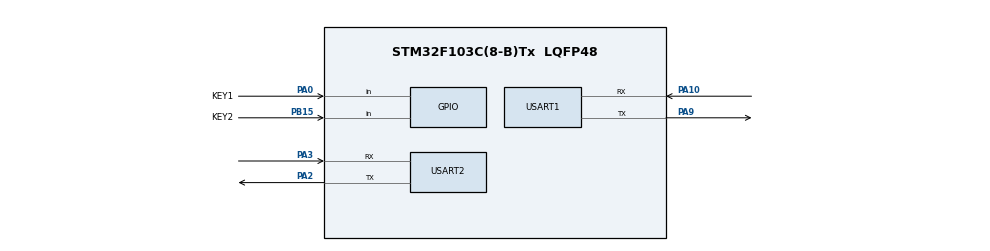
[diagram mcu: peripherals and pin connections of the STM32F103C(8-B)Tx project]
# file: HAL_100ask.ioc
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Mcu.Family=STM32F1
Mcu.Name=STM32F103C(8-B)Tx
Mcu.Package=LQFP48
NVIC.PriorityGroup=NVIC_PRIORITYGROUP_4
NVIC.USART2_IRQn=true\:0\:0\:false\:false\:true\:true\:true\:true
PA0-WKUP.GPIO_Label=KEY1
PA0-WKUP.GPIO_PuPd=GPIO_PULLDOWN
PA0-WKUP.Signal=GPIO_Input
PA10.Mode=Asynchronous
PA10.Signal=USART1_RX
PA13.Mode=Serial_Wire
PA13.Signal=SYS_JTMS-SWDIO
PA14.Mode=Serial_Wire
PA14.Signal=SYS_JTCK-SWCLK
PA2.Mode=Asynchronous
PA2.Signal=USART2_TX
PA3.Mode=Asynchronous
PA3.Signal=USART2_RX
PA9.Mode=Asynchronous
PA9.Signal=USART1_TX
PB15.GPIO_Label=KEY2
PB15.GPIO_PuPd=GPIO_PULLUP
PB15.Signal=GPIO_Input
PC14-OSC32_IN.Mode=LSE-External-Oscillator
PC14-OSC32_IN.Signal=RCC_OSC32_IN
PC15-OSC32_OUT.Mode=LSE-External-Oscillator
PC15-OSC32_OUT.Signal=RCC_OSC32_OUT
PD0-OSC_IN.Mode=HSE-External-Oscillator
PD0-OSC_IN.Signal=RCC_OSC_IN
PD1-OSC_OUT.Mode=HSE-External-Oscillator
PD1-OSC_OUT.Signal=RCC_OSC_OUT
ProjectManager.HeapSize=0x200
ProjectManager.StackSize=0x400
ProjectManager.TargetToolchain=MDK-ARM V5.32
RCC.AHBFreq_Value=72000000
RCC.APB1CLKDivider=RCC_HCLK_DIV2
RCC.APB1Freq_Value=36000000
RCC.APB1TimFreq_Value=72000000
RCC.APB2Freq_Value=72000000
RCC.APB2TimFreq_Value=72000000
RCC.HCLKFreq_Value=72000000
RCC.PLLMUL=RCC_PLL_MUL9
RCC.PLLSourceVirtual=RCC_PLLSOURCE_HSE
RCC.SYSCLKFreq_VALUE=72000000
RCC.SYSCLKSource=RCC_SYSCLKSOURCE_PLLCLK
RCC.USBFreq_Value=72000000
USART1.VirtualMode=VM_ASYNC
USART2.VirtualMode=VM_ASYNC
board=custom

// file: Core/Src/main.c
/* USER CODE BEGIN Header */
/**
  ******************************************************************************
  * @file           : main.c
  * @brief          : Main program body
  ******************************************************************************
  * @attention
  *
  * Copyright (c) 2024 STMicroelectronics.
  * All rights reserved.
  *
  * This software is licensed under terms that can be found in the LICENSE file
  * in the root directory of this software component.
  * If no LICENSE file comes with this software, it is provided AS-IS.
  *
  ******************************************************************************
  */
/* USER CODE END Header */
#include "main.h"
#include "usart.h"
#include "gpio.h"
#include "bsp.h"

/* USER CODE BEGIN PTD */
void Button1_Callback(void *btn);
void Button2_Callback(void *btn);
/* USER CODE END PTD */

//void SystemClock_Config(void);

/* USER CODE BEGIN 0 */
// 按键结构体
Button_t button1;
Button_t button2;

/* USER CODE END 0 */

int main(void)
{

  /* MCU Configuration--------------------------------------------------------*/

  /* Reset of all peripherals, Initializes the Flash interface and the Systick. */
  //HAL_Init();

  /* Configure the system clock */
  //SystemClock_Config();

  /* USER CODE BEGIN SysInit */
	bsp_Init();
  /* USER CODE END SysInit */

  /* Initialize all configured peripherals */

  MX_USART1_UART_Init();
  MX_USART2_UART_Init();

  /* Infinite loop */
  /* USER CODE BEGIN WHILE */
	    // 创建按钮
    Button_Create("Button1", &button1, Read_Key1_Level, 0); // 按键1，触发电平为低
    Button_Create("Button2", &button2, Read_Key2_Level, 1); // 按键2，触发电平为高

    // 绑定按键事件

		Button_Attach(&button1, BUTTON_UP, Button1_Callback);

    Button_Attach(&button2, BUTTON_UP, Button2_Callback);
		//bsp_LedOn(1);
  while (1)
  {
		    Button_Process(); // 定期处理按键状态
        HAL_Delay(20);    // 适当的延时
    /* USER CODE END WHILE */

  }
}

// /**
//   * @brief System Clock Configuration
//   * @retval None
//   */
// void SystemClock_Config(void)
// {
//   RCC_OscInitTypeDef RCC_OscInitStruct = {0};
//   RCC_ClkInitTypeDef RCC_ClkInitStruct = {0};

//   /** Initializes the RCC Oscillators according to the specified parameters
//   * in the RCC_OscInitTypeDef structure.
//   */
//   RCC_OscInitStruct.OscillatorType = RCC_OSCILLATORTYPE_HSE;
//   RCC_OscInitStruct.HSEState = RCC_HSE_ON;
//   RCC_OscInitStruct.HSEPredivValue = RCC_HSE_PREDIV_DIV1;
//   RCC_OscInitStruct.HSIState = RCC_HSI_ON;
//   RCC_OscInitStruct.PLL.PLLState = RCC_PLL_ON;
//   RCC_OscInitStruct.PLL.PLLSource = RCC_PLLSOURCE_HSE;
//   RCC_OscInitStruct.PLL.PLLMUL = RCC_PLL_MUL9;
//   if (HAL_RCC_OscConfig(&RCC_OscInitStruct) != HAL_OK)
//   {
//     Error_Handler();
//   }

//   /** Initializes the CPU, AHB and APB buses clocks
//   */
//   RCC_ClkInitStruct.ClockType = RCC_CLOCKTYPE_HCLK|RCC_CLOCKTYPE_SYSCLK
//                               |RCC_CLOCKTYPE_PCLK1|RCC_CLOCKTYPE_PCLK2;
//   RCC_ClkInitStruct.SYSCLKSource = RCC_SYSCLKSOURCE_PLLCLK;
//   RCC_ClkInitStruct.AHBCLKDivider = RCC_SYSCLK_DIV1;
//   RCC_ClkInitStruct.APB1CLKDivider = RCC_HCLK_DIV2;
//   RCC_ClkInitStruct.APB2CLKDivider = RCC_HCLK_DIV1;

//   if (HAL_RCC_ClockConfig(&RCC_ClkInitStruct, FLASH_LATENCY_2) != HAL_OK)
//   {
//     Error_Handler();
//   }
// }

// /* USER CODE BEGIN 4 */
// 按键1的回调函数
void Button1_Callback(void *btn) {
     bsp_LedToggle(1); // 按键1单击，翻转LED1状态
}

// 按键2的回调函数
void Button2_Callback(void *btn) {
  bsp_LedToggle(2);
}

// /* USER CODE END 4 */

// /**
//   * @brief  This function is executed in case of error occurrence.
//   * @retval None
//   */
// void Error_Handler(void)
// {
//   /* USER CODE BEGIN Error_Handler_Debug */
//   /* User can add his own implementation to report the HAL error return state */
//   __disable_irq();
//   while (1)
//   {
//   }
//   /* USER CODE END Error_Handler_Debug */
// }
